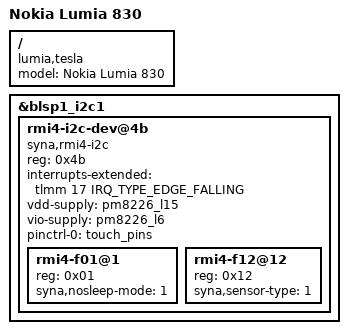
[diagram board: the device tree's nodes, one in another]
// SPDX-License-Identifier: BSD-3-Clause
/*
 * Copyright (c) 2021, Dominik Kobinski <Dominduchami@outlook.com>
 * Copyright (c) 2021, Ivaylo Ivanov <ivo.ivanov@null.net>
 */
/dts-v1/;

#include "qcom-msm8226-lumia-common.dtsi"

/ {
	model = "Nokia Lumia 830";
	compatible = "lumia,tesla","qcom,msm8226";
};

&blsp1_i2c1 {
	status = "okay";

	rmi4-i2c-dev@4b {
		compatible = "syna,rmi4-i2c";
		reg = <0x4b>;
		#address-cells = <1>;
		#size-cells = <0>;

		interrupts-extended = <&tlmm 17 IRQ_TYPE_EDGE_FALLING>;
		vdd-supply = <&pm8226_l15>;
		vio-supply = <&pm8226_l6>;

		pinctrl-names = "default";
		pinctrl-0 = <&touch_pins>;

		rmi4-f01@1 {
			reg = <0x01>;
			syna,nosleep-mode = <1>;
		};

		rmi4-f12@12 {
			reg = <0x12>;
			syna,sensor-type = <1>;
		};
	};
};
